# des register map
Vendor: Texas Instruments
Peripheral module from a debugger description file (folder cc32).
Registers are 32-bit, access not given, no defined reset value unless marked. A register's access mark holds for its fields unless they carry their own. Offsets are as the file gives them; lines under a group give offsets from that group; [hi:lo] are bit positions; {n}, {i} and the like mark numbered series; 'fields as' and 'values as' point back to an identical list; <NAME> marks a mode.

## des
0x00 KEY3_L — KEY3 (LSW) for 192-bit key
0x04 KEY3_H — KEY3 (MSW) for 192-bit key
0x08 KEY2_L — KEY2 (LSW) for 192-bit key
0x0C KEY2_H — KEY2 (MSW) for 192-bit key
0x10 KEY1_L — KEY1 (LSW) for 128-bit key/192-bit key
0x14 KEY1_H — KEY1 (LSW) for 128-bit key/192-bit key
0x18 IV_L — Initialization vector LSW
0x1C IV_H — Initialization vector MSW
0x20 CTRL rw
  [5:4] MODE — Select CBC ECB or CFB mode 0x0 ecb mode 0x1 cbc mode 0x2 cfb mode 0x3 reserved
0x24 LENGTH — Indicates the cryptographic data length in bytes for all modes. Once processing is started with this context this length decrements to zero. Data lengths up to (2^32 1) bytes are allowed. A write to this register triggers the engine to start using this context. For a Host read operation these registers return all-zeroes.
0x28 DATA_L — Data register(LSW) to read/write encrypted/decrypted data.
0x2C DATA_H — Data register(MSW) to read/write encrypted/decrypted data.
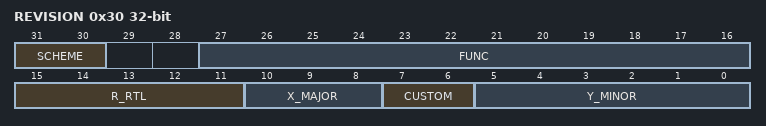
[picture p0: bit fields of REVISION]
0x30 REVISION rw
  [31:30] SCHEME
  [27:16] FUNC — Function indicates a software compatible module family. If there is no level of software compatibility a new Func number (and hence REVISION) should be assigned.
  [15:11] R_RTL — RTL Version (R) maintained by IP design owner. RTL follows a numbering such as X.Y.R.Z which are explained in this table. R changes ONLY when: (1) PDS uploads occur which may have been due to spec changes (2) Bug fixes occur (3) Resets to '0' when X or Y changes. Design team has an internal 'Z' (customer invisible) number which increments on every drop that happens due to DV and RTL updates. Z resets to 0 when R increments.
  [10:8] X_MAJOR — Major Revision (X) maintained by IP specification owner. X changes ONLY when: (1) There is a major feature addition. An example would be adding Master Mode to Utopia Level2. The Func field (or Class/Type in old PID format) will remain the same. X does NOT change due to: (1) Bug fixes (2) Change in feature parameters.
  [7:6] CUSTOM
  [5:0] Y_MINOR — Minor Revision (Y) maintained by IP specification owner. Y changes ONLY when: (1) Features are scaled (up or down). Flexibility exists in that this feature scalability may either be represented in the Y change or a specific register in the IP that indicates which features are exactly available. (2) When feature creeps from Is-Not list to Is list. But this may not be the case once it sees silicon; in which case X will change. Y does NOT change due to: (1) Bug fixes (2) Typos or clarifications (3) major functional/feature change/addition/deletion. Instead these changes may be reflected via R S X as applicable. Spec owner maintains a customer-invisible number 'S' which changes due to: (1) Typos/clarifications (2) Bug documentation. Note that this bug is not due to a spec change but due to implementation. Nevertheless the spec tracks the IP bugs. An RTL release (say for silicon PG1.1) that occurs due to bug fix should document the corresponding spec number (X.Y.S) in its release notes.
0x34 SYSCONFIG
0x38 SYSSTATUS
0x3C IRQSTATUS — This register indicates the interrupt status. If one of the interrupt bits is set the interrupt output will be asserted
0x40 IRQENABLE — This register contains an enable bit for each unique interrupt generated by the module. It matches the layout of DES_IRQSTATUS register. An interrupt is enabled when the bit in this register is set to 1 ****************************************************************************
